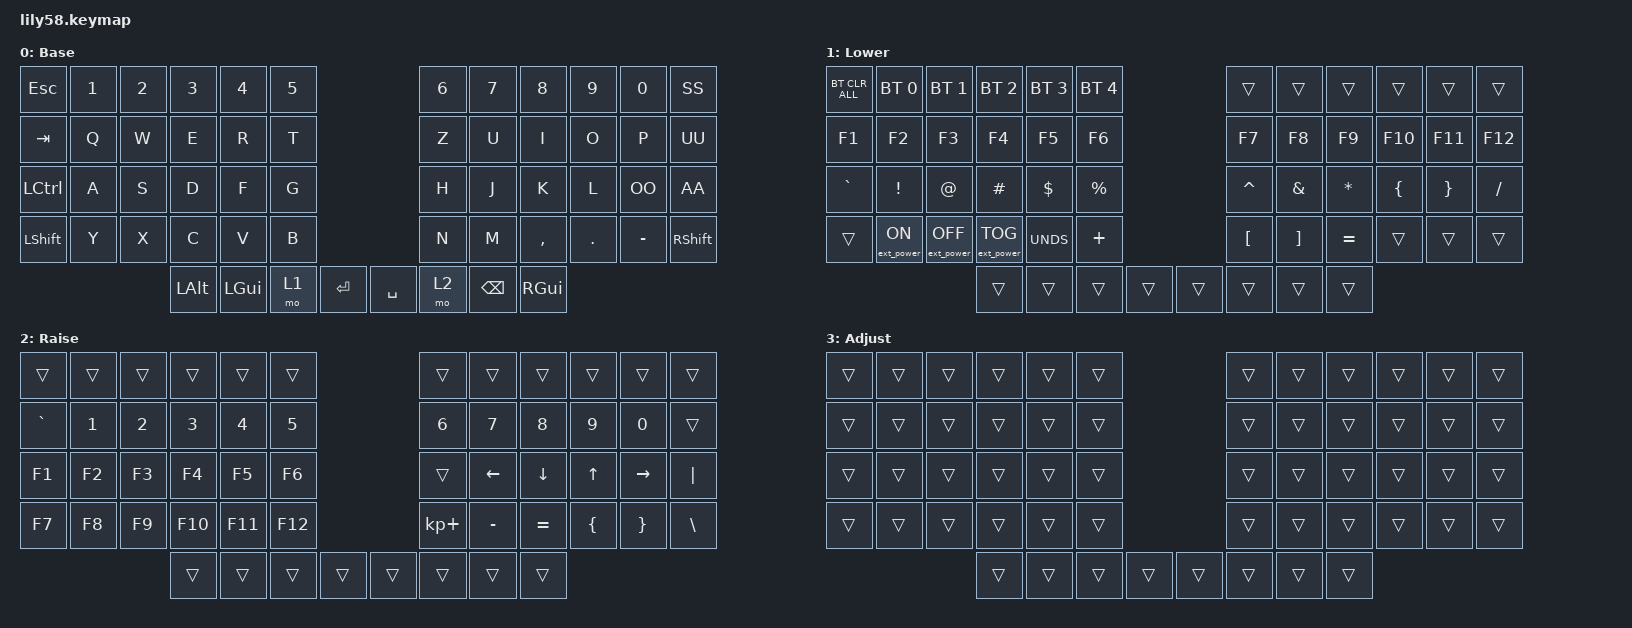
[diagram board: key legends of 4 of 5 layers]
/*
 * Optimized ZMK keymap for German layout (Mac DE)
 * Left-handed, developer-friendly
 * SPDX-License-Identifier: MIT
 */

#include <behaviors.dtsi>
#include <dt-bindings/zmk/keys.h>
#include <dt-bindings/zmk/bt.h>
#include <dt-bindings/zmk/ext_power.h>
#include <dt-bindings/zmk/pointing.h>

#define default_layer 0
#define lower_layer 1
#define raise_layer 2
#define adjust_layer 3
#define extra_layer 4

/ {
    keymap {
        compatible = "zmk,keymap";

        default_layer {
            display-name = "Base";
// ------------------------------------------------------------------------------------------------------------
// |  ESC  |  1  |  2  |  3   |  4   |  5   |                   |  6   |  7    |  8    |  9   |   0   |   ß   |
// |  TAB  |  Q  |  W  |  E   |  R   |  T   |                   |  Z   |  U    |  I    |  O   |   P   |   Ü   |
// |  CTRL |  A  |  S  |  D   |  F   |  G   |                   |  H   |  J    |  K    |  L   |   Ö   |   Ä   |
// | SHIFT |  Y  |  X  |  C   |  V   |  B   |                   |  N   |  M    |  ,    |  .   |   -   | SHIFT |
//                     | ALT  | GUI  | LOWER|  ENTER |  | SPACE | RAISE| BSPC  | GUI   |
            bindings = <
&kp ESC   &kp N1 &kp N2 &kp N3   &kp N4   &kp N5                     &kp N6 &kp N7   &kp N8    &kp N9  &kp N0   &kp SS
&kp TAB   &kp Q  &kp W  &kp E    &kp R    &kp T                      &kp Z  &kp U    &kp I     &kp O   &kp P    &kp UU
&kp LCTRL &kp A  &kp S  &kp D    &kp F    &kp G                      &kp H  &kp J    &kp K     &kp L   &kp OO   &kp AA
&kp LSHFT &kp Y  &kp X  &kp C    &kp V    &kp B                      &kp N  &kp M    &kp COMMA &kp DOT &kp MINUS &kp RSHFT
                        &kp LALT &kp LGUI &mo 1  &kp RET    &kp SPACE &mo 2  &kp BSPC &kp RGUI
            >;
        };

        lower_layer {
            display-name = "Lower";
// ------------------------------------------------------------------------------------------------------------
// | BTCLR | BT1 | BT2 |  BT3 |  BT4 |  BT5 |                   |      |       |       |      |       |       |
// |  F1   |  F2 |  F3 |  F4  |  F5  |  F6  |                   |  F7  |  F8   |  F9   |  F10 |  F11  |  F12  |
// |   `   |  !  |  @  |  #   |  $   |  %   |                   |  ^   |  &    |  *    |  [   |   ]   |   /   |
// |       |     |     |      |      |      |                   |  _   |  +    |  {   |   }   |   =   |       |
//                     |      |      |      |        |  |       |      |       |       |
            bindings = <
&bt BT_CLR_ALL &bt BT_SEL 0     &bt BT_SEL 1      &bt BT_SEL 2      &bt BT_SEL 3 &bt BT_SEL 4                 &trans    &trans    &trans    &trans    &trans    &trans
&kp F1         &kp F2           &kp F3            &kp F4            &kp F5       &kp F6                       &kp F7    &kp F8    &kp F9    &kp F10   &kp F11   &kp F12
&kp GRAVE      &kp EXCL         &kp AT            &kp HASH          &kp DOLLAR   &kp PRCNT                    &kp CARET &kp AMPS  &kp ASTRK &kp LBRC  &kp RBRC  &kp SLASH
&trans         &ext_power EP_ON &ext_power EP_OFF &ext_power EP_TOG &kp UNDS     &kp PLUS                     &kp LBKT  &kp RBKT  &kp EQUAL &trans    &trans    &trans
                                              &trans            &trans       &trans    &trans   &trans    &trans    &trans    &trans
            >;
        };

        raise_layer {
            display-name = "Raise";
// ------------------------------------------------------------------------------------------------------------
// |       |     |     |      |      |      |                   |      |       |       |      |       |       |
// |   `   |  1  |  2  |  3   |  4   |  5   |                   |  6   |   7   |   8   |  9   |   0   |       |
// |   F1  |  F2 |  F3 |  F4  |  F5  |  F6  |                   |      |   <-  |   v   |  ^   |  ->   |   |   |
// |   F7  |  F8 |  F9 |  F10 |  F11 |  F12 |                   |  +   |   -   |   =   |  [   |   ]   |   \   |
//                     |      |      |      |        |  |       |      |       |       |
            bindings = <
&trans    &trans &trans &trans  &trans  &trans                       &trans      &trans    &trans    &trans   &trans    &trans
&kp GRAVE &kp N1 &kp N2 &kp N3  &kp N4  &kp N5                       &kp N6      &kp N7    &kp N8    &kp N9   &kp N0    &trans
&kp F1    &kp F2 &kp F3 &kp F4  &kp F5  &kp F6                       &trans      &kp LEFT  &kp DOWN  &kp UP   &kp RIGHT &kp PIPE
&kp F7    &kp F8 &kp F9 &kp F10 &kp F11 &kp F12                      &kp KP_PLUS &kp MINUS &kp EQUAL &kp LBRC &kp RBRC  &kp BSLH
                        &trans  &trans  &trans    &trans   &trans    &trans      &trans    &trans
            >;
        };

        adjust_layer {
            display-name = "Adjust";
// ------------------------------------------------------------------------------------------------------------
// |       |     |     |      |      |      |                   |      |       |       |      |       |       |
// |       |     |     |      |      |      |                   |      |       |       |      |       |       |
// |       |     |     |      |      |      |                   |      |       |       |      |       |       |
// |       |     |     |      |      |      |                   |      |       |       |      |       |       |
//                     |      |      |      |        |  |       |      |       |       |
            bindings = <
&trans    &trans &trans &trans  &trans  &trans                       &trans      &trans    &trans    &trans   &trans    &trans
&trans    &trans &trans &trans  &trans  &trans                       &trans      &trans    &trans    &trans   &trans    &trans
&trans    &trans &trans &trans  &trans  &trans                       &trans      &trans    &trans    &trans   &trans    &trans
&trans    &trans &trans &trans  &trans  &trans                       &trans      &trans    &trans    &trans   &trans    &trans
                        &trans  &trans  &trans    &trans   &trans    &trans      &trans    &trans
            >;
        };

        extra_layer {
            display-name = "Extra";
// ------------------------------------------------------------------------------------------------------------
// |       |     |     |      |      |      |                   |      |       |       |      |       |       |
// |       |     |  ↑   |      |      |      |                   |      |       |       |      |       |       |
// |       |  ←   |  ↓   |  →   |      | SCRLD|                   |      |       |       |      |       |       |
// |       |     |      |      |      | SCRLU|   LCLK |  RCLK    |      |       |       |      |       |       |
//                     |      |      |      |        |  |       |      |       |       |
            bindings = <
&trans    &trans &trans &trans  &trans  &trans                       &trans      &trans    &trans    &trans   &trans    &trans
&trans    &trans &mmv MOVE_UP &trans  &trans  &trans                 &trans      &trans    &trans    &trans   &trans    &trans
&trans    &mmv MOVE_LEFT &mmv MOVE_DOWN &mmv MOVE_RIGHT  &trans  &msc SCRL_DOWN &trans    &trans    &trans   &trans   &trans    &trans
&trans    &trans &trans &trans  &trans  &msc SCRL_UP                  &mkp LCLK  &mkp RCLK &trans    &trans   &trans   &trans   &trans
                        &trans  &trans  &trans    &trans   &trans    &trans      &trans    &trans
            >;
        };
    };
};
